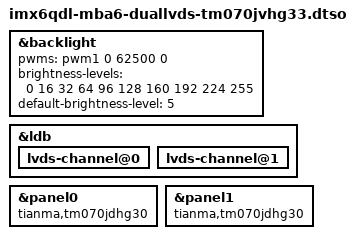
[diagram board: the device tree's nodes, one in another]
// SPDX-License-Identifier: GPL-2.0-only
/*
 * Copyright (c) 2019-2026 TQ-Systems GmbH <linux@ew.tq-group.com>,
 * D-82229 Seefeld, Germany.
 * Author: Markus Niebel
 * Author: Alexander Stein
 */

/dts-v1/;
/plugin/;

&backlight {
	pwms = <&pwm1 0 62500 0>;
	brightness-levels = <0 16 32 64 96 128 160 192 224 255>;
	default-brightness-level = <5>;
	status = "okay";
};

&ldb {
	status = "okay";

	lvds-channel@0 {
		status = "okay";
	};

	lvds-channel@1 {
		status = "okay";
	};
};

&panel0 {
	compatible = "tianma,tm070jdhg30";
	status = "okay";
};

&panel1 {
	compatible = "tianma,tm070jdhg30";
	status = "okay";
};
